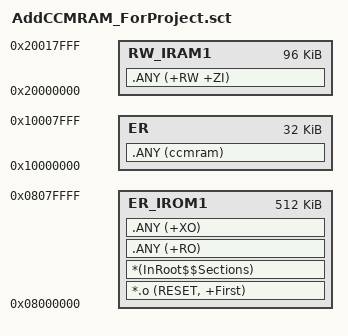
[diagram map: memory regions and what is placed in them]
; *************************************************************
; *** Scatter-Loading Description File generated by NOMAD   ***
; *************************************************************

LR_IROM1 0x08000000 0x00080000  {    ; load region size_region
  ER_IROM1 0x08000000 0x00080000  {  ; load address = execution address
   *.o (RESET, +First)
   *(InRoot$$Sections)
   .ANY (+RO)
   .ANY (+XO)
  }
  RW_IRAM1 0x20000000 0x00018000  {  ; RW data
   .ANY (+RW +ZI)
  }
  
  ER 0x10000000 0x00008000  {  ; load address = execution address
   .ANY (ccmram)
  }
}

